# MCXN947_cm33_core0 register map
Vendor: nxp.com; File version: 1.0
CPU: CM33 r2p0, little endian, MPU, FPU, VTOR, 3 interrupt priority bits
Registers are 32-bit, read-write, reset 0x0 unless marked. A register's access mark holds for its fields unless they carry their own. Offsets are from the block's base; [hi:lo] are bit positions.

## RTC0 — RTC
Base 0x4004C000
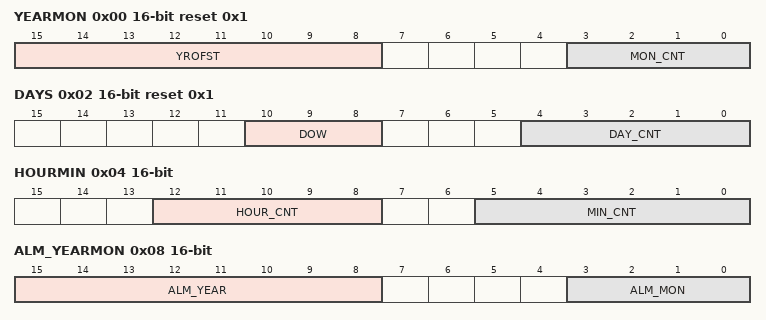
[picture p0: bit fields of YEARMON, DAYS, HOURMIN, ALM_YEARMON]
0x00 YEARMON 16-bit reset 0x1 — Year and Month Counters
  [15:8] YROFST — Year Offset Count Value
  [3:0] MON_CNT — Month Counter
    0=ILLEGAL_VALUE_0; 1=JANUARY; 2=FEBRUARY; 3=MARCH; 4=APRIL; 5=MAY; 6=JUNE; 7=JULY; 8=AUGUST; 9=SEPTEMBER; 10=OCTOBER; 11=NOVEMBER; 12=DECEMBER; 13=ILLEGAL_VALUE_13; 14=ILLEGAL_VALUE_14; 15=ILLEGAL_VALUE_15
0x02 DAYS 16-bit reset 0x1 — Days and Day-of-Week Counters
  [10:8] DOW — Day of Week Counter Value
    0=SUNDAY; 1=MONDAY; 2=TUESDAY; 3=WEDNESDAY; 4=THURSDAY; 5=FRIDAY; 6=SATURDAY
  [4:0] DAY_CNT — Days Counter Value
0x04 HOURMIN 16-bit — Hours and Minutes Counters
  [12:8] HOUR_CNT — Hours Counter Value
  [5:0] MIN_CNT — Minutes Counter Value
0x06 SECONDS 16-bit — Seconds Counters
  [5:0] SEC_CNT — Seconds Counter Value
0x08 ALM_YEARMON 16-bit — Year and Months Alarm
  [15:8] ALM_YEAR — Year Value for Alarm
  [3:0] ALM_MON — Months Value for Alarm
0x0A ALM_DAYS 16-bit — Days Alarm
  [4:0] ALM_DAY — Days Value for Alarm
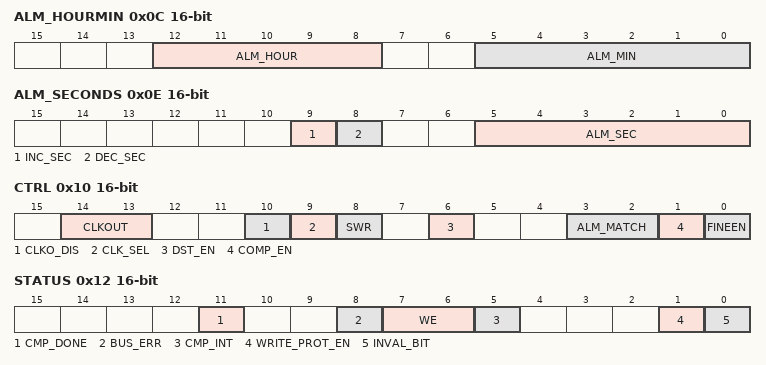
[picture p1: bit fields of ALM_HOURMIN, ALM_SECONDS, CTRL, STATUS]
0x0C ALM_HOURMIN 16-bit — Hours and Minutes Alarm
  [12:8] ALM_HOUR — Hours Value for Alarm
  [5:0] ALM_MIN — Minutes Value for Alarm
0x0E ALM_SECONDS 16-bit — Seconds Alarm
  [9] INC_SEC — Increment Seconds Counter by 1.
  [8] DEC_SEC — Decrement Seconds Counter by 1.
  [5:0] ALM_SEC — Seconds Alarm Value
0x10 CTRL 16-bit — Control
  [14:13] CLKOUT — RTC Clock Output Selection
    0=NO_OUTPUT_CLK (No output clock); 1=CLK_1HZ_FINE (Fine 1 Hz clock with both precise edges); 2=CLK_32_168KHZ (32.768 or 16.384 kHz clock); 3=CLK_1HZ_COARSE (Coarse 1 Hz clock with both precise edges)
  [10] CLKO_DIS — Clock Output Disable
    0=TO_OTHER_PERIPHERALS (The selected clock is output to other peripherals.); 1=NOT_TO_OTHER_PERIPHERALS (The selected clock is not output to other peripherals.)
  [9] CLK_SEL — RTC Clock Select
    0=CLK_16_384KHZ (16.384 kHz clock is selected); 1=CLK_32_768KHZ (32.768 kHz clock is selected)
  [8] SWR — Software Reset
    0=CLEARED (Software Reset cleared); 1=ASSERTED (Software Reset asserted)
  [6] DST_EN — Daylight Saving Enable
    0=DISABLED; 1=ENABLED
  [3:2] ALM_MATCH — Alarm Match
    0=HOURS (Only seconds, minutes, and hours matched.); 1=DAYS (Only seconds, minutes, hours, and days matched.); 2=MONTHS (Only seconds, minutes, hours, days, and months matched.); 3=YEAR (Only seconds, minutes, hours, days, months, and year (offset) matched.)
  [1] COMP_EN — Compensation Enable
    0=DISABLED (Coarse compensation is disabled.); 1=ENABLED (Coarse compensation is enabled.)
  [0] FINEEN — Fine Compensation Enable
    0=DISABLED (Fine compensation is disabled); 1=ENABLED (Fine compensation is enabled.)
0x12 STATUS 16-bit
  [11] CMP_DONE write-1-clears — Compensation Done
    0=DISABLED (Compensation busy or not enabled); 1=ENABLED (Compensation completed)
  [8] BUS_ERR write-1-clears — Bus Error
    0=NORMAL (Read and write accesses are normal.); 1=ASSERTED (Read or write accesses occurred when STATUS[INVAL_BIT] was asserted.)
  [7:6] WE — Write Enable
    2=LOCKED (Enable Write Protection - Registers are locked.)
  [5] CMP_INT ro — Compensation Interval
  [1] WRITE_PROT_EN ro — Write Protect Enable Status
    0=UNLOCKED (Registers are unlocked and can be accessed.); 1=LOCKED (Registers are locked and in read-only mode.)
  [0] INVAL_BIT ro — Invalidate CPU Read/Write Access
    0=VALID (Time and date counters can be read or written. Time and date is valid.); 1=INVALID (Time and date counter values are changing or time and date is invalid and cannot be read or written.)
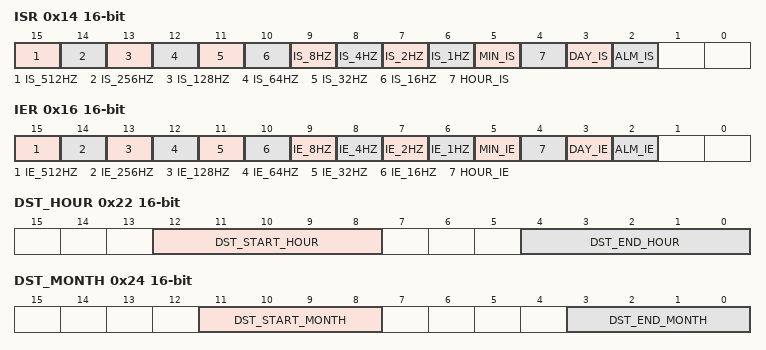
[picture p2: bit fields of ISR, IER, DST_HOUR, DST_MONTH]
0x14 ISR 16-bit write-1-clears — Interrupt Status
  [all] fields
    0=DEASSERTED (Interrupt is de-asserted.); 1=ASSERTED (Interrupt is asserted.)
  [15] IS_512HZ write-1-clears — 512 Hz Interval Interrupt Status
  [14] IS_256HZ write-1-clears — 256 Hz Interval Interrupt Status
  [13] IS_128HZ write-1-clears — 128 Hz Interval Interrupt Status
  [12] IS_64HZ write-1-clears — 64 Hz Interval Interrupt Status
  [11] IS_32HZ write-1-clears — 32 Hz Interval Interrupt Status
  [10] IS_16HZ write-1-clears — 16 Hz Interval Interrupt Status
  [9] IS_8HZ write-1-clears — 8 Hz Interval Interrupt Status
  [8] IS_4HZ write-1-clears — 4 Hz Interval Interrupt Status
  [7] IS_2HZ write-1-clears — 2 Hz Interval Interrupt Status
  [6] IS_1HZ write-1-clears — 1 Hz Interval Interrupt Status
  [5] MIN_IS write-1-clears — Minutes Interrupt Status
  [4] HOUR_IS write-1-clears — Hours Interrupt Status
  [3] DAY_IS write-1-clears — Days Interrupt Status
  [2] ALM_IS write-1-clears — Alarm Interrupt Status
0x16 IER 16-bit — Interrupt Enable
  [all] fields
    0=DISABLED (Interrupt is disabled.); 1=ENABLED (Interrupt is enabled.)
  [15] IE_512HZ — 512 Hz Interval Interrupt Enable
  [14] IE_256HZ — 256 Hz Interval Interrupt Enable
  [13] IE_128HZ — 128 Hz Interval Interrupt Enable
  [12] IE_64HZ — 64 Hz Interval Interrupt Enable
  [11] IE_32HZ — 32 Hz Interval Interrupt Enable
  [10] IE_16HZ — 16 Hz Interval Interrupt Enable
  [9] IE_8HZ — 8 Hz Interval Interrupt Enable
  [8] IE_4HZ — 4 Hz Interval Interrupt Enable
  [7] IE_2HZ — 2 Hz Interval Interrupt Enable
  [6] IE_1HZ — 1 Hz Interval Interrupt Enable
  [5] MIN_IE — Minutes Interrupt Enable
  [4] HOUR_IE — Hours Interrupt Enable
  [3] DAY_IE — Days Interrupt Enable
  [2] ALM_IE — Alarm Interrupt Enable
0x1C RTC_TEST2 16-bit ro — Sub Second Counter
  [15:0] SUB_SECOND_COUNT — Sub Second Counter Value
0x22 DST_HOUR 16-bit — Daylight Saving Hour
  [12:8] DST_START_HOUR — Daylight Saving Time (DST) Hours Start Value
  [4:0] DST_END_HOUR — Daylight Saving Time (DST) Hours End Value
0x24 DST_MONTH 16-bit — Daylight Saving Month
  [11:8] DST_START_MONTH — Daylight Saving Time (DST) Month Start Value
  [3:0] DST_END_MONTH — Daylight Saving Time (DST) Month End Value
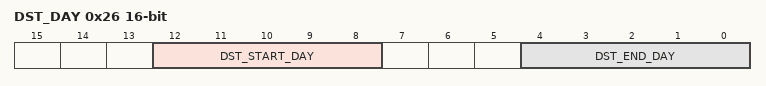
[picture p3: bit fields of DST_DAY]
0x26 DST_DAY 16-bit — Daylight Saving Day
  [12:8] DST_START_DAY — Daylight Saving Time (DST) Day Start Value
  [4:0] DST_END_DAY — Daylight Saving Time (DST) Day End Value
0x28 COMPEN 16-bit — Compensation
  [15:0] COMPEN_VAL — Compensation Value
